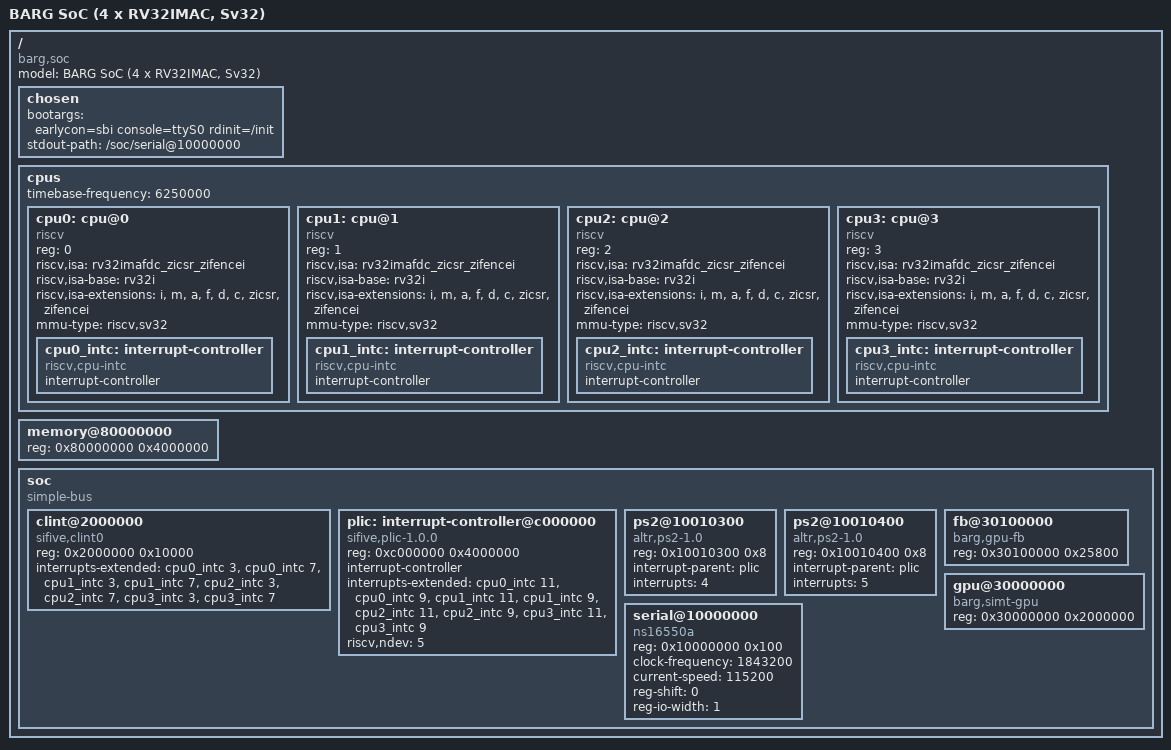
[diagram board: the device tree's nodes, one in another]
/* The BARG SoC as Linux and OpenSBI see it: four RV32IMAC harts with Sv32, 64 MB RAM, CLINT (four harts), 16550 UART (polled); the PLIC is not described (it has machine contexts only). */
/dts-v1/;
/ {
	#address-cells = <1>;
	#size-cells = <1>;
	compatible = "barg,soc";
	model = "BARG SoC (4 x RV32IMAC, Sv32)";

	chosen {
		bootargs = "earlycon=sbi console=ttyS0 rdinit=/init";
		stdout-path = "/soc/serial@10000000";
	};

	cpus {
		#address-cells = <1>;
		#size-cells = <0>;
		timebase-frequency = <6250000>;	// the core runs at 100 MHz; the CLINT counts once every 16 cycles
		cpu0: cpu@0 {
			device_type = "cpu";
			reg = <0>;
			status = "okay";
			compatible = "riscv";
			riscv,isa = "rv32imafdc_zicsr_zifencei";
			riscv,isa-base = "rv32i";
			riscv,isa-extensions = "i", "m", "a", "f", "d", "c", "zicsr", "zifencei";
			mmu-type = "riscv,sv32";
			cpu0_intc: interrupt-controller {
				#interrupt-cells = <1>;
				interrupt-controller;
				compatible = "riscv,cpu-intc";
			};
		};
		cpu1: cpu@1 {
			device_type = "cpu";
			reg = <1>;
			status = "okay";
			compatible = "riscv";
			riscv,isa = "rv32imafdc_zicsr_zifencei";
			riscv,isa-base = "rv32i";
			riscv,isa-extensions = "i", "m", "a", "f", "d", "c", "zicsr", "zifencei";
			mmu-type = "riscv,sv32";
			cpu1_intc: interrupt-controller {
				#interrupt-cells = <1>;
				interrupt-controller;
				compatible = "riscv,cpu-intc";
			};
		};
		cpu2: cpu@2 {
			device_type = "cpu";
			reg = <2>;
			status = "okay";
			compatible = "riscv";
			riscv,isa = "rv32imafdc_zicsr_zifencei";
			riscv,isa-base = "rv32i";
			riscv,isa-extensions = "i", "m", "a", "f", "d", "c", "zicsr", "zifencei";
			mmu-type = "riscv,sv32";
			cpu2_intc: interrupt-controller {
				#interrupt-cells = <1>;
				interrupt-controller;
				compatible = "riscv,cpu-intc";
			};
		};
		cpu3: cpu@3 {
			device_type = "cpu";
			reg = <3>;
			status = "okay";
			compatible = "riscv";
			riscv,isa = "rv32imafdc_zicsr_zifencei";
			riscv,isa-base = "rv32i";
			riscv,isa-extensions = "i", "m", "a", "f", "d", "c", "zicsr", "zifencei";
			mmu-type = "riscv,sv32";
			cpu3_intc: interrupt-controller {
				#interrupt-cells = <1>;
				interrupt-controller;
				compatible = "riscv,cpu-intc";
			};
		};
	};

	memory@80000000 {
		device_type = "memory";
		reg = <0x80000000 0x4000000>;
	};

	soc {
		#address-cells = <1>;
		#size-cells = <1>;
		compatible = "simple-bus";
		ranges;

		clint@2000000 {
			compatible = "sifive,clint0", "riscv,clint0";
			reg = <0x2000000 0x10000>;
			interrupts-extended = <&cpu0_intc 3>, <&cpu0_intc 7>, <&cpu1_intc 3>, <&cpu1_intc 7>, <&cpu2_intc 3>, <&cpu2_intc 7>, <&cpu3_intc 3>, <&cpu3_intc 7>;
		};

		plic: interrupt-controller@c000000 {
			compatible = "sifive,plic-1.0.0", "riscv,plic0";
			reg = <0xc000000 0x4000000>;
			#address-cells = <0>;
			#interrupt-cells = <1>;
			interrupt-controller;
			interrupts-extended = <&cpu0_intc 11>, <&cpu0_intc 9>, <&cpu1_intc 11>, <&cpu1_intc 9>, <&cpu2_intc 11>, <&cpu2_intc 9>, <&cpu3_intc 11>, <&cpu3_intc 9>;
			riscv,ndev = <5>;
		};

		ps2@10010300 {
			compatible = "altr,ps2-1.0";
			reg = <0x10010300 0x8>;
			interrupt-parent = <&plic>;
			interrupts = <4>;
		};

		ps2@10010400 {
			compatible = "altr,ps2-1.0";
			reg = <0x10010400 0x8>;
			interrupt-parent = <&plic>;
			interrupts = <5>;
		};

		fb@30100000 {
			compatible = "barg,gpu-fb";
			reg = <0x30100000 0x25800>;
		};

		gpu@30000000 {
			compatible = "barg,simt-gpu";
			reg = <0x30000000 0x2000000>;
			status = "okay";
		};

		serial@10000000 {
			compatible = "ns16550a";
			reg = <0x10000000 0x100>;
			clock-frequency = <1843200>;
			current-speed = <115200>;
			reg-shift = <0>;
			reg-io-width = <1>;
		};
	};
};
